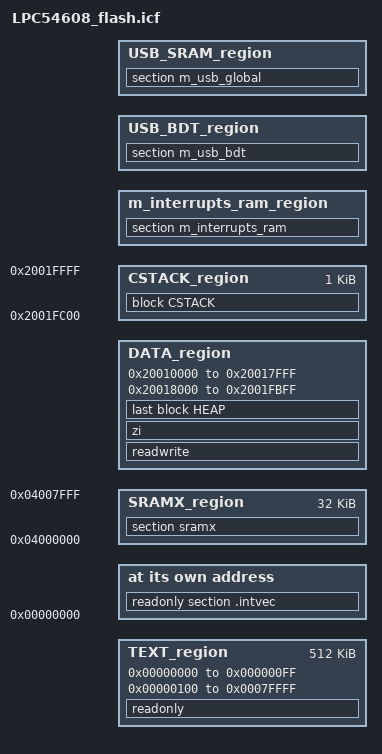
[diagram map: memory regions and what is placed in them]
/*
** ###################################################################
**     Processors:          LPC54628J512BD208
**                          LPC54628J512ET180
**
**     Compiler:            IAR ANSI C/C++ Compiler for ARM
**     Reference manual:    LPC5460x User manual Rev. 0.5 21 Jul 2016
**     Version:             rev. 1.0, 2016-06-17
**     Build:               b160720
**
**     Abstract:
**         Linker file for the IAR ANSI C/C++ Compiler for ARM
**
**     Copyright (c) 2016 Freescale Semiconductor, Inc.
**     All rights reserved.
**
**     
**     SPDX-License-Identifier: BSD-3-Clause
**
**     http:                 www.freescale.com
**     mail:                 support@freescale.com
**
** ###################################################################
*/

define symbol __ram_vector_table_size__ =  isdefinedsymbol(__ram_vector_table__) ? 0x000000E0 : 0;
define symbol __ram_vector_table_offset__ =  isdefinedsymbol(__ram_vector_table__) ? 0x000000DF : 0;

define symbol m_interrupts_start             = 0x00000000;
define symbol m_interrupts_end               = 0x000000FF;

define symbol m_text_start                   = 0x00000100;
define symbol m_text_end                     = 0x0007FFFF;

define symbol m_interrupts_ram_start         = 0x20000000;
define symbol m_interrupts_ram_end           = 0x20000000 + __ram_vector_table_offset__;

define symbol m_data_start                   = m_interrupts_ram_start + __ram_vector_table_size__;
define symbol m_data_end                     = 0x2000FFFF;

define symbol m_data_2_start                 = 0x20010000;
define symbol m_data_2_end                   = 0x20017FFF;

define symbol m_data_3_start                 = 0x20018000;
define symbol m_data_3_end                   = 0x2001FFFF;

define symbol m_sramx_start                  = 0x04000000;
define symbol m_sramx_end                    = 0x04007FFF;

/* USBRAM: 8K */
if (isdefinedsymbol(__usb_use_usbram__)) {
  define symbol m_usb_sram_start       = 0x40100000;
  define symbol m_usb_sram_end         = 0x40101FFF;
}

define symbol __ram_iap_start__              = 0x2000FF00;
define symbol __ram_iap_end__                = 0x2000FFFF;

/* Sizes */
if (isdefinedsymbol(__stack_size__)) {
  define symbol __size_cstack__        = __stack_size__;
} else {
  define symbol __size_cstack__        = 0x0400;
}

if (isdefinedsymbol(__heap_size__)) {
  define symbol __size_heap__          = __heap_size__;
} else {
  define symbol __size_heap__          = 0x0800;
}

define exported symbol __VECTOR_TABLE  = m_interrupts_start;
define exported symbol __VECTOR_RAM    = isdefinedsymbol(__ram_vector_table__) ? m_interrupts_ram_start : m_interrupts_start;
define exported symbol __RAM_VECTOR_TABLE_SIZE = __ram_vector_table_size__;

define memory mem with size = 4G;
define region TEXT_region             = mem:[from m_interrupts_start to m_interrupts_end]
                                      | mem:[from m_text_start to m_text_end];
define region DATA_region             = mem:[from m_data_start to m_data_end]
                                      | mem:[from m_data_2_start to m_data_2_end]
                                      | mem:[from m_data_3_start to m_data_3_end-__size_cstack__]
                                      - mem:[from __ram_iap_start__ to __ram_iap_end__];
define region SRAMX_region            = mem:[from m_sramx_start to m_sramx_end];
define region CSTACK_region           = mem:[from m_data_3_end-__size_cstack__+1 to m_data_3_end];
define region m_interrupts_ram_region = mem:[from m_interrupts_ram_start to m_interrupts_ram_end];

define block CSTACK    with alignment = 8, size = __size_cstack__   { };
define block HEAP      with alignment = 8, size = __size_heap__     { };

/* regions for USB */
if (isdefinedsymbol(__usb_use_usbram__)) {
  define region USB_BDT_region = mem:[from m_usb_sram_start to m_usb_sram_start + usb_bdt_size - 1];
  define region USB_SRAM_region = mem:[from m_usb_sram_start + usb_bdt_size to m_usb_sram_end];
  place in USB_BDT_region                   { section m_usb_bdt };
  place in USB_SRAM_region                  { section m_usb_global };
}

initialize by copy { readwrite };

if (isdefinedsymbol(__USE_DLIB_PERTHREAD))
{
  // Required in a multi-threaded application
  initialize by copy with packing = none { section __DLIB_PERTHREAD };
}

if (isdefinedsymbol(__usb_use_usbram__)) {
  do not initialize  { section .noinit, section m_usb_bdt, section m_usb_global };
} else {
  do not initialize  { section .noinit };
}

place at address mem: m_interrupts_start    { readonly section .intvec };
place in TEXT_region                        { readonly };
place in DATA_region                        { readwrite };
place in DATA_region                        { zi };
place in DATA_region                        { last block HEAP };
place in SRAMX_region                       { section sramx };
place in CSTACK_region                      { block CSTACK };
place in m_interrupts_ram_region            { section m_interrupts_ram };
